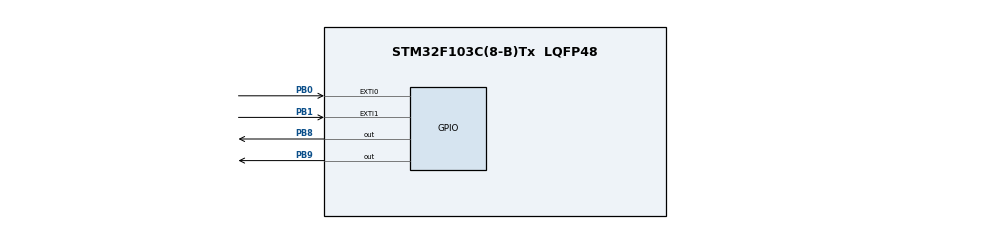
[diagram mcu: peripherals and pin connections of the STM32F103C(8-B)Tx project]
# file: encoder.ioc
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Mcu.Family=STM32F1
Mcu.Name=STM32F103C(8-B)Tx
Mcu.Package=LQFP48
NVIC.EXTI0_IRQn=true\:0\:0\:false\:false\:true\:true\:true\:true
NVIC.EXTI1_IRQn=true\:0\:0\:false\:false\:true\:true\:true\:true
NVIC.PriorityGroup=NVIC_PRIORITYGROUP_4
PA13.Mode=Serial_Wire
PA13.Signal=SYS_JTMS-SWDIO
PA14.Mode=Serial_Wire
PA14.Signal=SYS_JTCK-SWCLK
PB0.GPIO_ModeDefaultEXTI=GPIO_MODE_IT_FALLING
PB0.Signal=GPXTI0
PB1.GPIO_ModeDefaultEXTI=GPIO_MODE_IT_FALLING
PB1.Signal=GPXTI1
PB8.GPIO_ModeDefaultOutputPP=GPIO_MODE_OUTPUT_OD
PB8.GPIO_PuPd=GPIO_NOPULL
PB8.Signal=GPIO_Output
PB9.GPIO_ModeDefaultOutputPP=GPIO_MODE_OUTPUT_OD
PB9.GPIO_PuPd=GPIO_NOPULL
PB9.Signal=GPIO_Output
ProjectManager.HeapSize=0x200
ProjectManager.StackSize=0x400
ProjectManager.TargetToolchain=STM32CubeIDE
RCC.APB1Freq_Value=8000000
RCC.APB2Freq_Value=8000000
board=custom

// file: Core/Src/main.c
/* USER CODE BEGIN Header */
/**
  ******************************************************************************
  * @file           : main.c
  * @brief          : Main program body
  ******************************************************************************
  * @attention
  *
  * Copyright (c) 2026 STMicroelectronics.
  * All rights reserved.
  *
  * This software is licensed under terms that can be found in the LICENSE file
  * in the root directory of this software component.
  * If no LICENSE file comes with this software, it is provided AS-IS.
  *
  ******************************************************************************
  */
/* USER CODE END Header */
#include "main.h"
#include "gpio.h"

/* USER CODE BEGIN PV */
	extern int16_t Count;
/* USER CODE END PV */

void SystemClock_Config(void);

int main(void)
{

  /* MCU Configuration--------------------------------------------------------*/

  /* Reset of all peripherals, Initializes the Flash interface and the Systick. */
  HAL_Init();

  /* Configure the system clock */
  SystemClock_Config();

  /* Initialize all configured peripherals */
  MX_GPIO_Init();

  /* Infinite loop */
  /* USER CODE BEGIN WHILE */
	OLED_Init();

  while (1)
  {
//		OLED_ShowChar(1,1,'A');
//		OLED_ShowString(1,3,"HelloWorld");
//		OLED_ShowNum(2,1,12345,5);
//		OLED_ShowSignedNum(2,7,12345,5);
//		OLED_ShowHexNum(3,1,0xAA55,4);
//		OLED_ShowBinNum(4,1,0xAA55,16);
	  OLED_ShowSignedNum(1, 1, Count, 5);
    /* USER CODE END WHILE */

  }
}

void SystemClock_Config(void)
{
  RCC_OscInitTypeDef RCC_OscInitStruct = {0};
  RCC_ClkInitTypeDef RCC_ClkInitStruct = {0};

  /** Initializes the RCC Oscillators according to the specified parameters
  * in the RCC_OscInitTypeDef structure.
  */
  RCC_OscInitStruct.OscillatorType = RCC_OSCILLATORTYPE_HSI;
  RCC_OscInitStruct.HSIState = RCC_HSI_ON;
  RCC_OscInitStruct.HSICalibrationValue = RCC_HSICALIBRATION_DEFAULT;
  RCC_OscInitStruct.PLL.PLLState = RCC_PLL_NONE;
  if (HAL_RCC_OscConfig(&RCC_OscInitStruct) != HAL_OK)
  {
    Error_Handler();
  }

  /** Initializes the CPU, AHB and APB buses clocks
  */
  RCC_ClkInitStruct.ClockType = RCC_CLOCKTYPE_HCLK|RCC_CLOCKTYPE_SYSCLK
                              |RCC_CLOCKTYPE_PCLK1|RCC_CLOCKTYPE_PCLK2;
  RCC_ClkInitStruct.SYSCLKSource = RCC_SYSCLKSOURCE_HSI;
  RCC_ClkInitStruct.AHBCLKDivider = RCC_SYSCLK_DIV1;
  RCC_ClkInitStruct.APB1CLKDivider = RCC_HCLK_DIV1;
  RCC_ClkInitStruct.APB2CLKDivider = RCC_HCLK_DIV1;

  if (HAL_RCC_ClockConfig(&RCC_ClkInitStruct, FLASH_LATENCY_0) != HAL_OK)
  {
    Error_Handler();
  }
}

void Error_Handler(void)
{
  __disable_irq();
  while (1)
  {
  }
}
